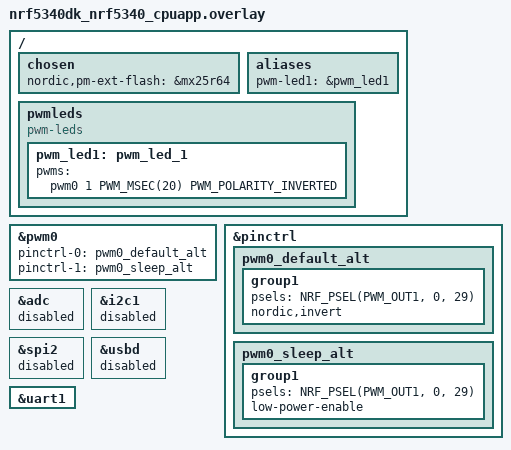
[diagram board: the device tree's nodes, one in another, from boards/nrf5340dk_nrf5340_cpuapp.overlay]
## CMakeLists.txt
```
#
# Copyright (c) 2022 Nordic Semiconductor ASA
#
# SPDX-License-Identifier: LicenseRef-Nordic-5-Clause
#

cmake_minimum_required(VERSION 3.20.0)

get_filename_component(MATTER_MODULE_ROOT $ENV{ZEPHYR_BASE}/../modules/lib/matter REALPATH)

# Set Kconfig root files that will be processed as a first Kconfig for used child images.
set(mcuboot_KCONFIG_ROOT ${MATTER_MODULE_ROOT}/config/nrfconnect/chip-module/Kconfig.mcuboot.root)
set(multiprotocol_rpmsg_KCONFIG_ROOT ${MATTER_MODULE_ROOT}/config/nrfconnect/chip-module/Kconfig.multiprotocol_rpmsg.root)
set(hci_rpmsg_KCONFIG_ROOT ${MATTER_MODULE_ROOT}/config/nrfconnect/chip-module/Kconfig.hci_rpmsg.root)

# For prj.conf the CONF_FILE is empty. In other case extract the exact file name from the path string.
if(CONF_FILE)
    get_filename_component(CONFIG_FILE_NAME ${CONF_FILE} NAME)
endif()

if(NOT CONFIG_FILE_NAME STREQUAL "prj_no_dfu.conf")
    set(PM_STATIC_YML_FILE ${CMAKE_CURRENT_SOURCE_DIR}/configuration/${BOARD}/pm_static_dfu.yml)
endif()

find_package(Zephyr HINTS $ENV{ZEPHYR_BASE})

project(matter-bridge)

set(COMMON_ROOT ${ZEPHYR_NRF_MODULE_DIR}/samples/matter/common)
set(NLIO_ROOT ${MATTER_MODULE_ROOT}/third_party/nlio/repo)
include(${MATTER_MODULE_ROOT}/config/nrfconnect/app/enable-gnu-std.cmake)
include(${MATTER_MODULE_ROOT}/src/app/chip_data_model.cmake)

# NORDIC SDK APP START
target_include_directories(app PRIVATE
    src
    ${COMMON_ROOT}/src
    ${NLIO_ROOT}/include
    ${MATTER_MODULE_ROOT}/zzz_generated/app-common
)

target_sources(app PRIVATE
    src/app_task.cpp
    src/main.cpp
    src/zigbee_shell.cpp
    src/Device.cpp
    src/zap-generated/IMClusterCommandHandler.cpp
    src/zap-generated/callback-stub.cpp
    ${COMMON_ROOT}/src/led_widget.cpp
)

if(CONFIG_CHIP_OTA_REQUESTOR OR CONFIG_MCUMGR_TRANSPORT_BT)
    target_sources(app PRIVATE ${COMMON_ROOT}/src/ota_util.cpp)
endif()

if(CONFIG_MCUMGR_TRANSPORT_BT)
    target_sources(app PRIVATE ${COMMON_ROOT}/src/dfu_over_smp.cpp)
endif()

chip_configure_data_model(app
    INCLUDE_SERVER
    BYPASS_IDL
    GEN_DIR src/zap-generated
    ZAP_FILE ${CMAKE_CURRENT_SOURCE_DIR}/src/bridge.zap
)
# NORDIC SDK APP END
```

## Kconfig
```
#
# Copyright (c) 2022 Nordic Semiconductor
#
# SPDX-License-Identifier: LicenseRef-Nordic-5-Clause
#
mainmenu "Matter Bridge sample application"

# Sample configuration used for Thread networking
if NET_L2_OPENTHREAD

choice OPENTHREAD_NORDIC_LIBRARY_CONFIGURATION
	default OPENTHREAD_NORDIC_LIBRARY_FTD
endchoice

choice OPENTHREAD_DEVICE_TYPE
	default OPENTHREAD_FTD
endchoice

endif # NET_L2_OPENTHREAD

config ZIGBEE_SHELL_DEVICE_NAME
	string "UART device name for Zigbee shell"
	default "UART_1"

source "${ZEPHYR_BASE}/../modules/lib/matter/config/nrfconnect/chip-module/Kconfig.features"
source "${ZEPHYR_BASE}/../modules/lib/matter/config/nrfconnect/chip-module/Kconfig.defaults"
source "Kconfig.zephyr"
```

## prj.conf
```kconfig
#
# Copyright (c) 2022 Nordic Semiconductor ASA
#
# SPDX-License-Identifier: LicenseRef-Nordic-5-Clause
#

# This sample uses Kconfig.defaults to set options common for all
# samples. This file should contain only options specific for this sample
# or overrides of default values.

# Enable CHIP
CONFIG_CHIP=y
CONFIG_CHIP_PROJECT_CONFIG="src/chip_project_config.h"
# 32768 == 0x8000
CONFIG_CHIP_DEVICE_PRODUCT_ID=32768
CONFIG_STD_CPP14=y

# Enable CHIP pairing automatically on application start.
CONFIG_CHIP_ENABLE_PAIRING_AUTOSTART=y

# Add support for LEDs and buttons on Nordic development kits
CONFIG_DK_LIBRARY=y

# Bluetooth Low Energy configuration
CONFIG_BT_DEVICE_NAME="MatterBridge"

# Other settings
CONFIG_THREAD_NAME=y
CONFIG_MPU_STACK_GUARD=y
CONFIG_RESET_ON_FATAL_ERROR=n

CONFIG_UART_ASYNC_API=y
CONFIG_UART_1_ASYNC=y
CONFIG_UART_1_INTERRUPT_DRIVEN=n
CONFIG_UART_1_NRF_HW_ASYNC=y
CONFIG_UART_1_NRF_HW_ASYNC_TIMER=2
CONFIG_NRFX_TIMER2=y
```

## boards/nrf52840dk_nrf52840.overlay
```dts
/* Copyright (c) 2022 Nordic Semiconductor ASA
 *
 * SPDX-License-Identifier: LicenseRef-Nordic-5-Clause
 */

/ {
	chosen {
		nordic,pm-ext-flash = &mx25r64;
	};
};


/ {
	/*
	* In some default configurations within the nRF Connect SDK,
	* e.g. on nRF52840, the chosen zephyr,entropy node is &cryptocell.
	* This devicetree overlay ensures that default is overridden wherever it
	* is set, as this application uses the RNG node for entropy exclusively.
	*/
	chosen {
		zephyr,entropy = &rng;
	};
};
```

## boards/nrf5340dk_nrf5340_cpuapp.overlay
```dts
/* Copyright (c) 2022 Nordic Semiconductor ASA
 *
 * SPDX-License-Identifier: LicenseRef-Nordic-5-Clause
 */

/ {
	chosen {
		nordic,pm-ext-flash = &mx25r64;
	};

	/*
	* By default, PWM module is only configured for led0 (LED1 on the board).
	* The light bulb app, however, uses LED2 to show the state of the lighting,
	* including its brightness level.
	*/
	aliases {
		pwm-led1 = &pwm_led1;
	};

	pwmleds {
		compatible = "pwm-leds";
		pwm_led1: pwm_led_1 {
			pwms = < &pwm0 1 PWM_MSEC(20) PWM_POLARITY_INVERTED>;
		};
	};
};

&pwm0 {
	pinctrl-0 = <&pwm0_default_alt>;
	pinctrl-1 = <&pwm0_sleep_alt>;
	pinctrl-names = "default", "sleep";
};

&pinctrl {
	pwm0_default_alt: pwm0_default_alt {
		group1 {
			psels = <NRF_PSEL(PWM_OUT1, 0, 29)>;
			nordic,invert;
		};
	};

	pwm0_sleep_alt: pwm0_sleep_alt {
		group1 {
			psels = <NRF_PSEL(PWM_OUT1, 0, 29)>;
			low-power-enable;
		};
	};
};

/* Disable unused peripherals to reduce power consumption */
&adc {
	status = "disabled";
};
&i2c1 {
	status = "disabled";
};
&spi2 {
	status = "disabled";
};
&usbd {
	status = "disabled";
};

/* Used to talk to the Zigbee board */
&uart1 {
	status = "okay";
};
```

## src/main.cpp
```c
/*
 * Copyright (c) 2022 Nordic Semiconductor ASA
 *
 * SPDX-License-Identifier: LicenseRef-Nordic-5-Clause
 */

#include "app_task.h"

#include <zephyr/logging/log.h>

#include <lib/support/CHIPMem.h>
#include <platform/CHIPDeviceLayer.h>

LOG_MODULE_REGISTER(app);

using namespace ::chip::DeviceLayer;

int main()
{
	int ret = 0;
	CHIP_ERROR err = CHIP_NO_ERROR;

	err = chip::Platform::MemoryInit();
	if (err != CHIP_NO_ERROR) {
		LOG_ERR("Platform::MemoryInit() failed");
		goto exit;
	}

	LOG_INF("Init CHIP stack");
	err = PlatformMgr().InitChipStack();
	if (err != CHIP_NO_ERROR) {
		LOG_ERR("PlatformMgr().InitChipStack() failed");
		goto exit;
	}

	LOG_INF("Starting CHIP task");
	err = PlatformMgr().StartEventLoopTask();
	if (err != CHIP_NO_ERROR) {
		LOG_ERR("PlatformMgr().StartEventLoopTask() failed");
		goto exit;
	}

	LOG_INF("Init Thread stack");
	err = ThreadStackMgr().InitThreadStack();
	if (err != CHIP_NO_ERROR) {
		LOG_ERR("ThreadStackMgr().InitThreadStack() failed");
		goto exit;
	}

	err = ConnectivityMgr().SetThreadDeviceType(ConnectivityManager::kThreadDeviceType_MinimalEndDevice);
	if (err != CHIP_NO_ERROR) {
		LOG_ERR("ConnectivityMgr().SetThreadDeviceType() failed");
		goto exit;
	}

	ret = GetAppTask().StartApp();
	if (ret != 0) {
		err = chip::System::MapErrorZephyr(ret);
	}

exit:
	return err == CHIP_NO_ERROR ? EXIT_SUCCESS : EXIT_FAILURE;
}
```

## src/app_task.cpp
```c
/*
 * Copyright (c) 2022 Nordic Semiconductor ASA
 *
 * SPDX-License-Identifier: LicenseRef-Nordic-5-Clause
 */

#include "app_task.h"
#include "led_widget.h"
#include "zigbee_shell.h"
#include "Device.h"

#include <app-common/zap-generated/attributes/Accessors.h>
#include <app/CommandHandler.h>
#include <app/reporting/reporting.h>
#include <app/server/OnboardingCodesUtil.h>
#include <app/server/Server.h>
#include <app/util/attribute-storage.h>
#include <credentials/DeviceAttestationCredsProvider.h>
#include <credentials/examples/DeviceAttestationCredsExample.h>
#include <lib/support/ZclString.h>
#include <platform/CHIPDeviceLayer.h>

#include <vector>

#include <dk_buttons_and_leds.h>

#include <zephyr/logging/log.h>
#include <zephyr/kernel.h>

LOG_MODULE_DECLARE(app);

using namespace ::chip;
using namespace ::chip::app;
using namespace ::chip::Credentials;
using namespace ::chip::DeviceLayer;

namespace
{
static constexpr size_t kAppEventQueueSize = 10;
static constexpr uint32_t kFactoryResetTriggerTimeout = 6000;

K_MSGQ_DEFINE(sAppEventQueue, sizeof(AppEvent), kAppEventQueueSize, alignof(AppEvent));
LEDWidget sStatusLED;
LEDWidget sUnusedLED;
LEDWidget sUnusedLED_1;
LEDWidget sUnusedLED_2;

ZigbeeShell sZbShell;

#define ZB_HA_DIMMABLE_LIGHT_DEVICE_ID  0x0101
#define ZB_AF_HA_PROFILE_ID		0x0104

static const int kNodeLabelSize = 32;
// Current ZCL implementation of Struct uses a max-size array of 254 bytes
static const int kDescriptorAttributeArraySize = 254;
static const int kFixedLabelAttributeArraySize = 254;

static EndpointId gCurrentEndpointId;
static EndpointId gFirstDynamicEndpointId;
static Device * gDevices[CHIP_DEVICE_CONFIG_DYNAMIC_ENDPOINT_COUNT]; // number of dynamic endpoints count

// Bridged devices
//std::vector<Device> Lights(CHIP_DEVICE_CONFIG_DYNAMIC_ENDPOINT_COUNT, Device("Default", "None"));
std::vector<Device> Lights(CHIP_DEVICE_CONFIG_DYNAMIC_ENDPOINT_COUNT, Device());

// (taken from chip-devices.xml)
#define DEVICE_TYPE_BRIDGED_NODE 0x0013
// (taken from lo-devices.xml)
#define DEVICE_TYPE_LO_ON_OFF_LIGHT 0x0100

// (taken from chip-devices.xml)
#define DEVICE_TYPE_ROOT_NODE 0x0016
// (taken from chip-devices.xml)
#define DEVICE_TYPE_BRIDGE 0x000e

// Device Version for dynamic endpoints:
#define DEVICE_VERSION_DEFAULT 1

/* REVISION definitions:
 */

#define ZCL_DESCRIPTOR_CLUSTER_REVISION (1u)
#define ZCL_BRIDGED_DEVICE_BASIC_INFORMATION_CLUSTER_REVISION (1u)
#define ZCL_FIXED_LABEL_CLUSTER_REVISION (1u)
#define ZCL_ON_OFF_CLUSTER_REVISION (4u)
#define ZCL_TEMPERATURE_SENSOR_CLUSTER_REVISION (4u)
#define ZCL_BRIDGED_DEVICE_BASIC_INFORMATION_FEATURE_MAP (0u)
#define ZCL_TEMPERATURE_SENSOR_FEATURE_MAP (0u)

/* BRIDGED DEVICE ENDPOINT: contains the following clusters:
   - On/Off
   - Descriptor
   - Bridged Device Basic Information
*/

// Declare On/Off cluster attributes
DECLARE_DYNAMIC_ATTRIBUTE_LIST_BEGIN(onOffAttrs)
DECLARE_DYNAMIC_ATTRIBUTE(Clusters::OnOff::Attributes::OnOff::Id, BOOLEAN, 1, 0), /* on/off */
    DECLARE_DYNAMIC_ATTRIBUTE(Clusters::OnOff::Attributes::ClusterRevision::Id, INT16U, ZCL_ON_OFF_CLUSTER_REVISION, 0),
	DECLARE_DYNAMIC_ATTRIBUTE_LIST_END();

// Declare Descriptor cluster attributes
DECLARE_DYNAMIC_ATTRIBUTE_LIST_BEGIN(descriptorAttrs)
DECLARE_DYNAMIC_ATTRIBUTE(Clusters::Descriptor::Attributes::DeviceTypeList::Id, ARRAY, kDescriptorAttributeArraySize,
                          0), /* device list */
    DECLARE_DYNAMIC_ATTRIBUTE(Clusters::Descriptor::Attributes::ServerList::Id, ARRAY, kDescriptorAttributeArraySize,
                              0), /* server list */
    DECLARE_DYNAMIC_ATTRIBUTE(Clusters::Descriptor::Attributes::ClientList::Id, ARRAY, kDescriptorAttributeArraySize,
                              0), /* client list */
    DECLARE_DYNAMIC_ATTRIBUTE(Clusters::Descriptor::Attributes::PartsList::Id, ARRAY, kDescriptorAttributeArraySize,
                              0), /* parts list */
    DECLARE_DYNAMIC_ATTRIBUTE(Clusters::Descriptor::Attributes::ClusterRevision::Id, INT16U, ZCL_DESCRIPTOR_CLUSTER_REVISION,
                              0), /* cluster revision */
	DECLARE_DYNAMIC_ATTRIBUTE_LIST_END();

// Declare Bridged Device Basic Information cluster attributes
DECLARE_DYNAMIC_ATTRIBUTE_LIST_BEGIN(bridgedDeviceBasicAttrs)
DECLARE_DYNAMIC_ATTRIBUTE(chip::app::Clusters::BridgedDeviceBasicInformation::Attributes::NodeLabel::Id, CHAR_STRING,
                          kNodeLabelSize, 0), /* NodeLabel */
    DECLARE_DYNAMIC_ATTRIBUTE(chip::app::Clusters::BridgedDeviceBasicInformation::Attributes::Reachable::Id, BOOLEAN, 1,
                              0), /* Reachable */
    DECLARE_DYNAMIC_ATTRIBUTE(chip::app::Clusters::BridgedDeviceBasicInformation::Attributes::ClusterRevision::Id, INT16U,
                              ZCL_BRIDGED_DEVICE_BASIC_INFORMATION_CLUSTER_REVISION, 0), /* cluster revision */
	DECLARE_DYNAMIC_ATTRIBUTE_LIST_END();

// Declare Cluster List for Bridged Light endpoint
// TODO: It's not clear whether it would be better to get the command lists from
// the ZAP config on our last fixed endpoint instead.
constexpr CommandId onOffIncomingCommands[] = {
    app::Clusters::OnOff::Commands::Off::Id,
    app::Clusters::OnOff::Commands::On::Id,
    app::Clusters::OnOff::Commands::Toggle::Id,
    app::Clusters::OnOff::Commands::OffWithEffect::Id,
    app::Clusters::OnOff::Commands::OnWithRecallGlobalScene::Id,
    app::Clusters::OnOff::Commands::OnWithTimedOff::Id,
    kInvalidCommandId,
};

DECLARE_DYNAMIC_CLUSTER_LIST_BEGIN(bridgedLightClusters)
DECLARE_DYNAMIC_CLUSTER(Clusters::OnOff::Id, onOffAttrs, onOffIncomingCommands, nullptr),
    DECLARE_DYNAMIC_CLUSTER(Clusters::Descriptor::Id, descriptorAttrs, nullptr, nullptr),
    DECLARE_DYNAMIC_CLUSTER(chip::app::Clusters::BridgedDeviceBasicInformation::Id, bridgedDeviceBasicAttrs, nullptr,
                            nullptr) DECLARE_DYNAMIC_CLUSTER_LIST_END;

// Declare Bridged Light endpoint
DECLARE_DYNAMIC_ENDPOINT(bridgedLightEndpoint, bridgedLightClusters);

bool sIsThreadProvisioned;
bool sIsThreadEnabled;
bool sHaveBLEConnections;

k_timer sFunctionTimer;
} /* namespace */

AppTask AppTask::sAppTask;

DataVersion gLightDataVersions[ArraySize(bridgedLightClusters)];

const EmberAfDeviceType gRootDeviceTypes[]          = { { DEVICE_TYPE_ROOT_NODE, DEVICE_VERSION_DEFAULT } };
const EmberAfDeviceType gAggregateNodeDeviceTypes[] = { { DEVICE_TYPE_BRIDGE, DEVICE_VERSION_DEFAULT } };

const EmberAfDeviceType gBridgedOnOffDeviceTypes[] = { { DEVICE_TYPE_LO_ON_OFF_LIGHT, DEVICE_VERSION_DEFAULT },
                                                       { DEVICE_TYPE_BRIDGED_NODE, DEVICE_VERSION_DEFAULT } };


int AddDeviceEndpoint(Device * dev, EmberAfEndpointType * ep, const Span<const EmberAfDeviceType> & deviceTypeList,
                      const Span<DataVersion> & dataVersionStorage, chip::EndpointId parentEndpointId)
{
    uint8_t index = 0;
    while (index < CHIP_DEVICE_CONFIG_DYNAMIC_ENDPOINT_COUNT)
    {
        if (NULL == gDevices[index])
        {
            gDevices[index] = dev;
            EmberAfStatus ret;
            while (true)
            {
                dev->SetEndpointId(gCurrentEndpointId);
                ret =
                    emberAfSetDynamicEndpoint(index, gCurrentEndpointId, ep, dataVersionStorage, deviceTypeList, parentEndpointId);
                if (ret == EMBER_ZCL_STATUS_SUCCESS)
                {
                    ChipLogProgress(DeviceLayer, "Added device %s to dynamic endpoint %d (index=%d)", dev->GetName(),
                                    gCurrentEndpointId, index);
                    return index;
                }
                else if (ret != EMBER_ZCL_STATUS_DUPLICATE_EXISTS)
                {
                    return -1;
                }
                // Handle wrap condition
                if (++gCurrentEndpointId < gFirstDynamicEndpointId)
                {
                    gCurrentEndpointId = gFirstDynamicEndpointId;
                }
            }
        }
        index++;
    }
    ChipLogError(DeviceLayer, "Failed to add dynamic endpoint: No endpoints available!");
	return -1;
}

CHIP_ERROR RemoveDeviceEndpoint(Device * dev)
{
	for (uint8_t index = 0; index < CHIP_DEVICE_CONFIG_DYNAMIC_ENDPOINT_COUNT; index++)
	{
		if (gDevices[index] == dev)
		{
			EndpointId ep   = emberAfClearDynamicEndpoint(index);
			gDevices[index] = NULL;
			ChipLogProgress(DeviceLayer, "Removed device %s from dynamic endpoint %d (index=%d)", dev->GetName(), ep, index);
			// Silence complaints about unused ep when progress logging
			// disabled.
			UNUSED_VAR(ep);
			return CHIP_NO_ERROR;
		}
	}
	return CHIP_ERROR_INTERNAL;
}

EmberAfStatus HandleReadBridgedDeviceBasicAttribute(Device * dev, chip::AttributeId attributeId, uint8_t * buffer,
						    uint16_t maxReadLength)
{
	using namespace chip::app::Clusters::BridgedDeviceBasicInformation::Attributes;
	ChipLogProgress(DeviceLayer, "HandleReadBridgedDeviceBasicAttribute: attrId=%" PRIu32 ", maxReadLength=%u", attributeId,
                    maxReadLength);

	if ((attributeId == Reachable::Id) && (maxReadLength == 1))
	{
		*buffer = dev->IsReachable() ? 1 : 0;
	}
	else if ((attributeId == NodeLabel::Id) && (maxReadLength == 32))
	{
		MutableByteSpan zclNameSpan(buffer, maxReadLength);
		MakeZclCharString(zclNameSpan, dev->GetName());
	}
	else if ((attributeId == FeatureMap::Id) && (maxReadLength == 4))
	{
		uint32_t featureMap = ZCL_BRIDGED_DEVICE_BASIC_INFORMATION_FEATURE_MAP;
		memcpy(buffer, &featureMap, sizeof(featureMap));
	}
	else if ((attributeId == ClusterRevision::Id) && (maxReadLength == 4))
	{
		uint16_t clusterRevision = ZCL_BRIDGED_DEVICE_BASIC_INFORMATION_CLUSTER_REVISION;
		memcpy(buffer, &clusterRevision, sizeof(clusterRevision));
	}
	else
	{
		return EMBER_ZCL_STATUS_FAILURE;
	}

	return EMBER_ZCL_STATUS_SUCCESS;
}

EmberAfStatus HandleReadOnOffAttribute(Device * dev, chip::AttributeId attributeId, uint8_t * buffer, uint16_t maxReadLength)
{
	ChipLogProgress(DeviceLayer, "HandleReadOnOffAttribute: attrId=%" PRIu32 ", maxReadLength=%u", attributeId, maxReadLength);

	if ((attributeId == Clusters::OnOff::Attributes::OnOff::Id) && (maxReadLength == 1))
	{
		*buffer = dev->IsOn() ? 1 : 0;
	}
	else if ((attributeId == Clusters::OnOff::Attributes::ClusterRevision::Id) && (maxReadLength == 4))
	{
		uint16_t clusterRevision = ZCL_ON_OFF_CLUSTER_REVISION;
		memcpy(buffer, &clusterRevision, sizeof(clusterRevision));
	}
	else
	{
		return EMBER_ZCL_STATUS_FAILURE;
	}

	return EMBER_ZCL_STATUS_SUCCESS;
}

EmberAfStatus HandleWriteOnOffAttribute(Device * dev, chip::AttributeId attributeId, uint8_t * buffer)
{
	ChipLogProgress(DeviceLayer, "HandleWriteOnOffAttribute: attrId=%" PRIu32, attributeId);

	ReturnErrorCodeIf((attributeId != Clusters::OnOff::Attributes::OnOff::Id) || (!dev->IsReachable()), EMBER_ZCL_STATUS_FAILURE);
	dev->SetOnOff(*buffer == 1);
	sZbShell.ZclCmd(dev->GetZbAddr(), dev->GetZbEp(), ZigbeeShell::kCluster_OnOff, (*buffer == 1)?(true):(false));
	return EMBER_ZCL_STATUS_SUCCESS;
}

EmberAfStatus emberAfExternalAttributeReadCallback(EndpointId endpoint, ClusterId clusterId,
						   const EmberAfAttributeMetadata * attributeMetadata, uint8_t * buffer,
						   uint16_t maxReadLength)
{
    using namespace Clusters;

	uint16_t endpointIndex = emberAfGetDynamicIndexFromEndpoint(endpoint);

	if ((endpointIndex < CHIP_DEVICE_CONFIG_DYNAMIC_ENDPOINT_COUNT) && (gDevices[endpointIndex] != NULL))
	{
		Device * dev = gDevices[endpointIndex];

		if (clusterId == BridgedDeviceBasicInformation::Id)
		{
			return HandleReadBridgedDeviceBasicAttribute(dev, attributeMetadata->attributeId, buffer, maxReadLength);
		}
		else if (clusterId == OnOff::Id)
		{
			return HandleReadOnOffAttribute(dev, attributeMetadata->attributeId, buffer, maxReadLength);
		}
	}

	return EMBER_ZCL_STATUS_FAILURE;
}

EmberAfStatus emberAfExternalAttributeWriteCallback(EndpointId endpoint, ClusterId clusterId,
						    const EmberAfAttributeMetadata * attributeMetadata, uint8_t * buffer)
{
	uint16_t endpointIndex = emberAfGetDynamicIndexFromEndpoint(endpoint);

	if (endpointIndex < CHIP_DEVICE_CONFIG_DYNAMIC_ENDPOINT_COUNT)
	{
		Device * dev = gDevices[endpointIndex];

		if ((dev->IsReachable()) && (clusterId == Clusters::OnOff::Id))
		{
			return HandleWriteOnOffAttribute(dev, attributeMetadata->attributeId, buffer);
		}
	}

	return EMBER_ZCL_STATUS_FAILURE;
}

namespace {
void CallReportingCallback(intptr_t closure)
{
    auto path = reinterpret_cast<app::ConcreteAttributePath *>(closure);
    MatterReportingAttributeChangeCallback(*path);
    Platform::Delete(path);
}

void ScheduleReportingCallback(Device * dev, ClusterId cluster, AttributeId attribute)
{
    auto * path = Platform::New<app::ConcreteAttributePath>(dev->GetEndpointId(), cluster, attribute);
    DeviceLayer::PlatformMgr().ScheduleWork(CallReportingCallback, reinterpret_cast<intptr_t>(path));
}
} // anonymous namespace

void HandleDeviceStatusChanged(Device * dev, Device::Changed_t itemChangedMask)
{
    using namespace chip::app::Clusters;
	if (itemChangedMask & Device::kChanged_Reachable)
	{
		ScheduleReportingCallback(dev, BridgedDeviceBasicInformation::Id, BridgedDeviceBasicInformation::Attributes::Reachable::Id);
	}

	if (itemChangedMask & Device::kChanged_State)
	{
		ScheduleReportingCallback(dev, OnOff::Id, OnOff::Attributes::OnOff::Id);
	}

	if (itemChangedMask & Device::kChanged_Name)
	{
		ScheduleReportingCallback(dev, BridgedDeviceBasicInformation::Id, BridgedDeviceBasicInformation::Attributes::NodeLabel::Id);
	}
}

bool emberAfActionsClusterInstantActionCallback(app::CommandHandler * commandObj, const app::ConcreteCommandPath & commandPath,
                                                const Clusters::Actions::Commands::InstantAction::DecodableType & commandData)
{
    // No actions are implemented, just return status NotFound.
    commandObj->AddStatus(commandPath, Protocols::InteractionModel::Status::NotFound);
    return true;
}


int AppTask::Init()
{
	int ret;

	/* Initialize LEDs */
	LEDWidget::InitGpio();
	LEDWidget::SetStateUpdateCallback(LEDStateUpdateHandler);

	sStatusLED.Init(DK_LED1);
	sUnusedLED.Init(DK_LED2);
	sUnusedLED_1.Init(DK_LED3);
	sUnusedLED_2.Init(DK_LED4);

	UpdateStatusLED();

	memset(gDevices, 0, sizeof(gDevices));

	// Whenever bridged device changes its state
	for (size_t i = 0; i < Lights.size(); ++i)
	{
		Lights[i].SetChangeCallback(&HandleDeviceStatusChanged);
	}

	/* Init Zigbee stack */
	sZbShell.SetEventCallback(ZigbeeEventHandler);
	ret = sZbShell.BdbStart();
	if (ret) {
		LOG_ERR("BdbStart() failed");
		return ret;
	}

	/* Initialize buttons */
	ret = dk_buttons_init(ButtonEventHandler);
	if (ret) {
		LOG_ERR("dk_buttons_init() failed");
		return ret;
	}

	/* Initialize function timer */
	k_timer_init(&sFunctionTimer, &AppTask::TimerEventHandler, nullptr);
	k_timer_user_data_set(&sFunctionTimer, this);

	/* Init ZCL Data Model and start server */
	static chip::CommonCaseDeviceServerInitParams initParams;
	(void) initParams.InitializeStaticResourcesBeforeServerInit();
	chip::Server::GetInstance().Init(initParams);

	/* Initialize device attestation config */
	SetDeviceAttestationCredentialsProvider(Examples::GetExampleDACProvider());
	ConfigurationMgr().LogDeviceConfig();
	PrintOnboardingCodes(chip::RendezvousInformationFlags(chip::RendezvousInformationFlag::kBLE));

	// Set starting endpoint id where dynamic endpoints will be assigned, which
	// will be the next consecutive endpoint id after the last fixed endpoint.
	gFirstDynamicEndpointId = static_cast<chip::EndpointId>(
		static_cast<int>(emberAfEndpointFromIndex(static_cast<uint16_t>(emberAfFixedEndpointCount() - 1))) + 1);
	gCurrentEndpointId = gFirstDynamicEndpointId;

	// Disable last fixed endpoint, which is used as a placeholder for all of the
	// supported clusters so that ZAP will generate the requisite code.
	emberAfEndpointEnableDisable(emberAfEndpointFromIndex(static_cast<uint16_t>(emberAfFixedEndpointCount() - 1)), false);

	// A bridge has root node device type on EP0 and aggregate node device type (bridge) at EP1
	emberAfSetDeviceTypeList(0, Span<const EmberAfDeviceType>(gRootDeviceTypes));
	emberAfSetDeviceTypeList(1, Span<const EmberAfDeviceType>(gAggregateNodeDeviceTypes));

	return 0;
}

int AppTask::StartApp()
{
	int ret = Init();

	if (ret) {
		LOG_ERR("AppTask.Init() failed");
		return ret;
	}

	AppEvent event = {};

	while (true) {
		k_msgq_get(&sAppEventQueue, &event, K_FOREVER);
		DispatchEvent(event);
	}
}

void AppTask::PostEvent(const AppEvent &event)
{
	if (k_msgq_put(&sAppEventQueue, &event, K_NO_WAIT)) {
		LOG_INF("Failed to post event to app task event queue");
	}
}

void AppTask::DispatchEvent(const AppEvent &event)
{
	int err;
	uint16_t InputCluster[] = {ZigbeeShell::Cluster_t::kCluster_OnOff};
	uint16_t OutputCluster[] = {};

	switch (event.Type) {
	case AppEvent::FunctionPress:
		FunctionPressHandler();
		break;
	case AppEvent::FunctionRelease:
		FunctionReleaseHandler();
		break;
	case AppEvent::FunctionTimer:
		FunctionTimerEventHandler();
		break;
	case AppEvent::UpdateLedState:
		event.UpdateLedStateEvent.LedWidget->UpdateState();
		break;
	case AppEvent::NetworkRejoin:
		err = sZbShell.ZdoMatchDesc(0xfffd, 0xfffd, ZB_AF_HA_PROFILE_ID, 1, InputCluster, 0, OutputCluster);
		if (err) {
			LOG_ERR("Fail to broadcast MatchDesc");
		}
		break;
	case AppEvent::DeviceAnnounceRsp:
		err = sZbShell.ZdoActiveEpReq(event.zdo.addr);
		if (err) {
			LOG_ERR("Fail to request active ep");
		}
		break;
	case AppEvent::ActiveEpRsp:
		err = sZbShell.ZdoSimpleDescReq(event.zdo.addr, event.zdo.ep);
		if (err) {
			LOG_ERR("Fail to request simple descriptor");
		}
		break;
	case AppEvent::SimpleDescRsp:
		err = sZbShell.ZclAttrRead(event.zdo.addr,
					   event.zdo.ep,
					   ZB_AF_HA_PROFILE_ID,
					   ZigbeeShell::kCluster_OnOff,
					   ZigbeeShell::kOnOffAttr_OnOff);
		if (err) {
			LOG_ERR("Fail to request simple descriptor");
		}
		break;
	case AppEvent::StartNetworkSteering:
		err = sZbShell.NetworkSteering();
		if (err) {
			LOG_ERR("Fail to start network steering");
		}
		break;
	default:
		LOG_INF("Unknown event received");
		break;
	}
}

void AppTask::FunctionPressHandler()
{
	sAppTask.StartFunctionTimer(kFactoryResetTriggerTimeout);
	sAppTask.mFunction = TimerFunction::FactoryReset;
}

void AppTask::FunctionReleaseHandler()
{
	if (sAppTask.mFunction == TimerFunction::FactoryReset) {
		sUnusedLED_2.Set(false);
		sUnusedLED_1.Set(false);
		sUnusedLED.Set(false);

		UpdateStatusLED();

		sAppTask.CancelFunctionTimer();
		sAppTask.mFunction = TimerFunction::NoneSelected;
		LOG_INF("Factory Reset has been Canceled");
	}
}

void AppTask::FunctionTimerEventHandler()
{
	if (sAppTask.mFunction == TimerFunction::FactoryReset) {
		sAppTask.mFunction = TimerFunction::NoneSelected;
		LOG_INF("Factory Reset triggered");

		sStatusLED.Set(true);
		sUnusedLED.Set(true);
		sUnusedLED_1.Set(true);
		sUnusedLED_2.Set(true);

		ConfigurationMgr().InitiateFactoryReset();
	}
}

void AppTask::LEDStateUpdateHandler(LEDWidget &ledWidget)
{
	sAppTask.PostEvent(AppEvent{ AppEvent::UpdateLedState, &ledWidget });
}

void AppTask::UpdateStatusLED()
{
	/* Update the status LED.
	 *
	 * If thread and service provisioned, keep the LED On constantly.
	 *
	 * If the system has ble connection(s) uptill the stage above, THEN blink the LED at an even
	 * rate of 100ms.
	 *
	 * Otherwise, blink the LED On for a very short time. */
	if (sIsThreadProvisioned && sIsThreadEnabled) {
		sStatusLED.Set(true);
	} else if (sHaveBLEConnections) {
		sStatusLED.Blink(100, 100);
	} else {
		sStatusLED.Blink(50, 950);
	}
}

void AppTask::ChipEventHandler(const ChipDeviceEvent *event, intptr_t /* arg */)
{
	switch (event->Type) {
	case DeviceEventType::kCHIPoBLEAdvertisingChange:
		sHaveBLEConnections = ConnectivityMgr().NumBLEConnections() != 0;
		UpdateStatusLED();
		break;
	case DeviceEventType::kThreadStateChange:
		sIsThreadProvisioned = ConnectivityMgr().IsThreadProvisioned();
		sIsThreadEnabled = ConnectivityMgr().IsThreadEnabled();
		UpdateStatusLED();
		break;
	default:
		break;
	}
}

void AppTask::ButtonEventHandler(uint32_t buttonState, uint32_t hasChanged)
{
	if (DK_BTN1_MSK & buttonState & hasChanged) {
		GetAppTask().PostEvent(AppEvent{ AppEvent::FunctionPress });
	} else if (DK_BTN1_MSK & hasChanged) {
		GetAppTask().PostEvent(AppEvent{ AppEvent::FunctionRelease });
	}

	if (DK_BTN2_MSK & buttonState & hasChanged) {
		GetAppTask().PostEvent(AppEvent{ AppEvent::StartNetworkSteering });
	}
}

void AppTask::ZigbeeEventHandler(ZigbeeShell * shell, ZigbeeShell::Event_t event)
{
	LOG_INF("Zigbee event: %d", event);
	switch (event) {
	case ZigbeeShell::kEvent_NetworkRejoin:
		GetAppTask().PostEvent(AppEvent{ AppEvent::NetworkRejoin, shell->mEvent.Bdb});
		break;
	case ZigbeeShell::kEvent_DeviceAnnounceRsp:
		GetAppTask().PostEvent(AppEvent{ AppEvent::DeviceAnnounceRsp, shell->mEvent.Zdo});
		break;
	case ZigbeeShell::kEvent_ActiveEpRsp:
		GetAppTask().PostEvent(AppEvent{ AppEvent::ActiveEpRsp, shell->mEvent.Zdo});
		break;
	case ZigbeeShell::kEvent_SimpleDescRsp:
		LOG_INF("addr:0x%04hx ep:%d dev_id:0x%04hx",
			shell->mEvent.Zdo.addr,
			shell->mEvent.Zdo.ep,
			shell->mEvent.Zdo.dev_id);
		if (shell->mEvent.Zdo.dev_id != ZB_HA_DIMMABLE_LIGHT_DEVICE_ID) {
			return;
		}
		for (auto &light : Lights)
		{
			if ((light.GetZbAddr() == shell->mEvent.Zcl.addr) &&
				(light.GetZbEp() == shell->mEvent.Zcl.ep)) {
				LOG_INF("Device existed");
				return;
			}
		}
		for (auto &light : Lights)
		{
			if (!strcmp(light.GetName(), "none")) {
				if (AddDeviceEndpoint(&light, &bridgedLightEndpoint,
					Span<const EmberAfDeviceType>(gBridgedOnOffDeviceTypes),
								      Span<DataVersion>(gLightDataVersions), 1) == 0) {
					light.SetName("Light");
					light.SetZbAddr(shell->mEvent.Zdo.addr);
					light.SetZbEp(shell->mEvent.Zdo.ep);
					light.SetReachable(true);
					GetAppTask().PostEvent(AppEvent{ AppEvent::SimpleDescRsp, shell->mEvent.Zdo});
				} else {
					LOG_ERR("Zigbee event: %d", event);
				}
				break;
			}
		}
		break;
	case ZigbeeShell::kEvent_ZclAttrRead:
		for (auto &light : Lights)
		{
			if ((light.GetZbAddr() != shell->mEvent.Zcl.addr) ||
				(light.GetZbEp() != shell->mEvent.Zcl.ep)) {
				continue;
			}
			if (shell->mEvent.Zcl.cluster_id == ZigbeeShell::kCluster_OnOff &&
				shell->mEvent.Zcl.attr_id == ZigbeeShell::kOnOffAttr_OnOff &&
				shell->mEvent.Zcl.type == ZigbeeShell::kZclAttrType_BOOL) {
				if (!strncmp(shell->mEvent.Zcl.value, "True", shell->mEvent.Zcl.len)) {
					light.SetOnOff(true);
				} else if (!strncmp(shell->mEvent.Zcl.value, "False", shell->mEvent.Zcl.len)) {
					light.SetOnOff(false);
				} else {
					LOG_ERR("Wrong attr value");
				}
				break;
			}
		}
		break;
	default:
		LOG_WRN("Unknown event received");
		break;
	}

}

void AppTask::CancelFunctionTimer()
{
	k_timer_stop(&sFunctionTimer);
}

void AppTask::StartFunctionTimer(uint32_t timeoutInMs)
{
	k_timer_start(&sFunctionTimer, K_MSEC(timeoutInMs), K_NO_WAIT);
}

void AppTask::TimerEventHandler(k_timer *timer)
{
	GetAppTask().PostEvent(AppEvent{ AppEvent::FunctionTimer });
}
```

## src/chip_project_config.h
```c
/*
 * Copyright (c) 2022 Nordic Semiconductor ASA
 *
 * SPDX-License-Identifier: LicenseRef-Nordic-5-Clause
 */

/**
 *    @file
 *          Example project configuration file for CHIP.
 *
 *          This is a place to put application or project-specific overrides
 *          to the default configuration values for general CHIP features.
 *
 */

#pragma once

/* Use a default pairing code if one hasn't been provisioned in flash. */
#define CHIP_DEVICE_CONFIG_USE_TEST_SETUP_PIN_CODE 20202021
#define CHIP_DEVICE_CONFIG_USE_TEST_SETUP_DISCRIMINATOR 0xF00

// overrides CHIP_DEVICE_CONFIG_DYNAMIC_ENDPOINT_COUNT in CHIPProjectConfig
#define CHIP_DEVICE_CONFIG_DYNAMIC_ENDPOINT_COUNT 16
```

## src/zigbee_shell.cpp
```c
/*
 * Copyright (c) 2022 Nordic Semiconductor ASA
 *
 * SPDX-License-Identifier: LicenseRef-Nordic-5-Clause
 */

#include "zigbee_shell.h"
#include <zephyr/logging/log.h>
#include <zephyr/drivers/uart.h>

LOG_MODULE_DECLARE(zigbee_shell);

size_t ZigbeeShell::ShellRspHandler(ZigbeeShell *shell, const char *data, size_t len)
{
	char *p;

	p = strstr(data, ZB_SHELL_MSG_PROMPT);
	if (p != NULL) {
		LOG_DBG("Shell command finished");
		return p - data + strlen(ZB_SHELL_MSG_PROMPT);
	}

	return 0;
}

size_t ZigbeeShell::GeneralRspHandler(ZigbeeShell *shell, const char *data, size_t len)
{
	char *p;

	p = strstr((char *)data, ZB_SHELL_MSG_CMD_DONE);
	if (p != NULL) {
		LOG_DBG("General command finished - Done");
		shell->mZigbeeCmd.result = 0;
		return p - data + strlen(ZB_SHELL_MSG_CMD_DONE);
	}
	p = strstr((char *)data, ZB_SHELL_MSG_CMD_ERROR);
	if (p != NULL) {
		LOG_ERR("General command finished - Error");
		shell->mZigbeeCmd.result = -EINVAL;
		return p - data + strlen(ZB_SHELL_MSG_CMD_ERROR);
	}

	return 0;
}

size_t ZigbeeShell::ZclAttrReadRspHandler(ZigbeeShell *shell,const char *data, size_t len)
{
	char *p, *end;
	int attr_id;
	uint8_t type;
	size_t ret;

	p = strstr((char *)data, ZB_SHELL_MSG_CMD_ERROR);
	if (p != NULL) {
		LOG_ERR("Zcl attr read finished - Error");
		return p - data + strlen(ZB_SHELL_MSG_CMD_ERROR);
	}
	p = strstr((char *)data, ZB_SHELL_MSG_CMD_DONE);
	if (p == NULL) {
		LOG_DBG("Wait for more response");
		return 0;
	}
	ret = p - data + strlen(ZB_SHELL_MSG_CMD_DONE);
	p = strstr(data, "ID: ");
	if (p == NULL) {
		LOG_WRN("attr id missed");
		return ret;
	} else {
		p = p + strlen("ID: ");
		attr_id = strtol(p, &end, 10);
		if (p == end) {
			LOG_WRN("Can't get attr id");
			return ret;
		}
	}
	p = strstr(data, "Type: ");
	if (p == NULL) {
		LOG_WRN("attr type missed");
		return ret;
	} else {
		p = p + strlen("Type: ");
		type = strtol(p, &end, 16);
		if (p == end) {
			LOG_WRN("Can't get attr type");
			return ret;
		}
	}
	p = strstr(data, "Value: ");
	if (p == NULL) {
		LOG_WRN("Attr Value missed");
		return ret;
	}

	char *value_end = nullptr;

	p = p + strlen("Value: ");
	value_end = strstr(p, "\r\n");
	if (value_end == NULL) {
		LOG_WRN("Can't get attr value");
		return ret;
	}
	if ((value_end - p) > ZB_ZCL_MAX_ATTR_SIZE) {
		LOG_ERR("Fail to parse attr value");
		return 0;
	}
	memset(shell->mEvent.Zcl.value, 0, sizeof(shell->mEvent.Zcl.value));
	shell->mEvent.Zcl.len = value_end - p;
	shell->mEvent.Zcl.type = type;
	strncpy(shell->mEvent.Zcl.value, p, shell->mEvent.Zcl.len);
	LOG_INF("ID: %d Type: %x Value: %s", attr_id, type, shell->mEvent.Zcl.value);
	shell->mEvent_CB(shell, kEvent_ZclAttrRead);

	return ret;
}

size_t ZigbeeShell::ZdoActiveEpRspHandler(ZigbeeShell *shell, const char *data, size_t len)
{
	const char *p;
	uint16_t dev_addr;
	size_t ret;

	p = strstr((char *)data, ZB_SHELL_MSG_CMD_ERROR);
	if (p != NULL) {
		LOG_ERR("Zdo active endpoint request finished - Error");
		return p - data + strlen(ZB_SHELL_MSG_CMD_ERROR);
	}
	p = strstr((char *)data, ZB_SHELL_MSG_CMD_DONE);
	if (p == NULL) {
		LOG_DBG("Wait for more response");
		return 0;
	}
	ret = p - data + strlen(ZB_SHELL_MSG_CMD_DONE);
	p = data;
	for (;;) {
		p = strstr(p, "src_addr=");
		if (p == NULL) {
			break;
		} else {
			p = p + strlen("src_addr=");
			dev_addr = strtol(p, NULL, 16);
			p = strstr(p, "ep=");
			if (p == NULL) {
				break;
			} else {
				p = p + strlen("ep=");
				for (;;) {
					char *end;
					int ep;

					ep = strtol(p, &end, 10);
					if (p == end) {
						break;
					}
					shell->mEvent.Zdo.addr = dev_addr;
					shell->mEvent.Zdo.ep = ep;
					shell->mEvent_CB(shell, kEvent_ActiveEpRsp);
					if (*end == ',') {
						p = end + 1;
					} else {
						break;
					}
				}
			}
		}
	}
	return ret;
}

size_t ZigbeeShell::ZdoSimpleDescRspHandler(ZigbeeShell *shell, const char *data, size_t len)
{
	char *p;
	uint16_t dev_addr;
	size_t ret;

	p = strstr((char *)data, ZB_SHELL_MSG_CMD_ERROR);
	if (p != NULL) {
		LOG_ERR("Zdo simple descriptor request finished - Error");
		return p - data + strlen(ZB_SHELL_MSG_CMD_ERROR);
	}
	p = strstr((char *)data, ZB_SHELL_MSG_CMD_DONE);
	if (p == NULL) {
		LOG_DBG("Wait for more response");
		return 0;
	}
	ret = p - data + strlen(ZB_SHELL_MSG_CMD_DONE);
	p = strstr(data, "src_addr=");
	if (p == NULL) {
		return ret;
	} else {
		dev_addr = strtol(p + strlen("src_addr="), NULL, 16);
	}
	p = strstr(data, "ep=");
	if (p == NULL) {
		return ret;
	} else {
		char *end;
		int ep;
		int dev_id;

		p = p + strlen("ep=");
		ep = strtol(p, &end, 10);
		if (p != end) {
			p = strstr(data, "app_dev_id=");
			p = p + strlen("app_dev_id=");
			dev_id = strtol(p, &end, 16);
			if (p != end) {
				LOG_INF("addr: 0x%4hx, active ep: %d device id: %04hx",
					dev_addr, ep, dev_id);
				shell->mEvent.Zdo.addr = dev_addr;
				shell->mEvent.Zdo.ep = ep;
				shell->mEvent.Zdo.dev_id = dev_id;
				shell->mEvent_CB(shell, kEvent_SimpleDescRsp);
			}
		}
	}
	return ret;
}

void ZigbeeShell::UartWorkHandler(struct k_work *work)
{
	size_t ret = 0, parsed = 0, total_parsed = 0;

	ZigbeeShell *c = reinterpret_cast<ZigbeeShell*>((reinterpret_cast<char*>(work) - reinterpret_cast<int>((&(static_cast<ZigbeeShell*>(0)->mUartWork)))));
	if (c->mZigbeeCmd.handler == nullptr) {
		k_sem_give(&c->mCmdSem);
		return;
	}
	memset(c->mParserBuffer, 0, sizeof(c->mParserBuffer));
	ret = ring_buf_peek(&c->mShellRspRb, (uint8_t *)c->mParserBuffer, UNPARSED_BUF_LEN);
	if (ret == 0 || ret > UNPARSED_BUF_LEN) {
		LOG_ERR("Fail to peek ring buffer");
	}
	LOG_HEXDUMP_DBG(c->mParserBuffer, ret, "data to parse");
	parsed = c->mZigbeeCmd.handler(c, c->mParserBuffer, ret);
	if (parsed > 0) {
		k_sem_give(&c->mCmdSem);
	}
	total_parsed = (parsed > total_parsed) ? parsed : total_parsed;

	parsed = c->ParseShellMessage(c->mParserBuffer);
	total_parsed = (parsed > total_parsed) ? parsed : total_parsed;
	if (total_parsed > 0) {
		/* Remove parsed data from ring buffer */
		ret = ring_buf_get(&c->mShellRspRb, NULL, total_parsed);
		if(ret != total_parsed) {
			LOG_ERR("Fail to release from ring buffer");
		} else {
			LOG_INF("Release %d from buffer", ret);
		}
	}
}

int ZigbeeShell::WriteCmd(const char *cmd, ZigbeeResponseHandler rspHandler)
{
	int err = 0;
	size_t len;

	len = strlen(cmd);
	if (len + 2 > MAX_ZIGBEE_CMD_LEN) {
		LOG_INF("Not enough buffer to put Zigbee shell command");
		return -ENOMEM;
	}
	memset(mZigbeeCmd.command, 0, sizeof(mZigbeeCmd.command));
	memcpy(mZigbeeCmd.command, cmd, len);
	mZigbeeCmd.command[len] = '\r';
	mZigbeeCmd.command[len + 1] = '\n';
	mZigbeeCmd.handler = rspHandler;
	err = uart_tx(mUartDev, (const uint8_t *)mZigbeeCmd.command, strlen(mZigbeeCmd.command), 10);
	if (err) {
		LOG_ERR("uart_tx fail: %d", err);
	}
	k_sem_take(&mCmdSem, K_FOREVER);

	return mZigbeeCmd.result;
}

void ZigbeeShell::UartCallback(const struct device *dev, struct uart_event *evt, void *user_data)
{
	int err;
	static uint16_t pos;
	uint32_t ret;
	ZigbeeShell *shell = reinterpret_cast<ZigbeeShell *>(user_data);

	switch (evt->type) {
	case UART_TX_DONE:
		LOG_DBG("Tx sent %d bytes", evt->data.tx.len);
		break;

	case UART_TX_ABORTED:
		LOG_ERR("Tx aborted");
		break;

	case UART_RX_RDY:
		LOG_HEXDUMP_DBG(evt->data.rx.buf, evt->data.rx.len, "Uart RX");
		if (evt->data.rx.len > ring_buf_space_get(&shell->mShellRspRb)) {
			LOG_ERR("Not enough buffer to store data! Drop old data.");
			ret = ring_buf_get(&shell->mShellRspRb,
					   NULL,
					   evt->data.rx.len - ring_buf_space_get(&shell->mShellRspRb));
			LOG_ERR("Drop %d of ring buffer", ret);
		}
		/* Store received data to the ring buffer. */
		ret = ring_buf_put(&shell->mShellRspRb, evt->data.rx.buf + pos, evt->data.rx.len);
		if (ret != evt->data.rx.len) {
			LOG_ERR("Fail to put to ring buffer");
		}
		k_work_submit(&shell->mUartWork);
		pos += evt->data.rx.len;
		break;

	case UART_RX_BUF_REQUEST:
	{
		pos = 0;
		LOG_DBG("RX_REQUEST: %p", shell->mNextUartBuf);
		err = uart_rx_buf_rsp(shell->mUartDev,
				      shell->mNextUartBuf,
				      sizeof(shell->mUartRxBuf[0]));
		if (err) {
			LOG_WRN("UART RX buf rsp: %d", err);
		}
		break;
	}

	case UART_RX_BUF_RELEASED:
		LOG_DBG("RX_RELEASED: %p", evt->data.rx_buf.buf);
		shell->mNextUartBuf = evt->data.rx_buf.buf;
		break;

	case UART_RX_DISABLED:
		LOG_ERR("RX_DISABLED");
		break;

	case UART_RX_STOPPED:
		LOG_ERR("RX_STOPPED");
		break;
	}
}

size_t ZigbeeShell::ParseShellMessage(const char * szMsg)
{
	size_t parsed = 0, total_parsed = 0;
	char *p, *end;

	/* Parse network join message */
	p = strstr(szMsg, ZB_SHELL_MSG_JOIN_NETWORK);
	if (p != nullptr) {
		p = strstr(p, "Extended PAN ID: ");
		if (p != nullptr) {
			p = p + strlen("Extended PAN ID: ");
			memcpy(this->mEvent.Bdb.ext_pan_id, p, EXT_PAN_ID_SIZE);
			this->mEvent.Bdb.ext_pan_id[EXT_PAN_ID_SIZE] = 0;
			p = strstr(p, "PAN ID: ");
			if (p != nullptr) {
				p = p + strlen("PAN ID: ");
				this->mEvent.Bdb.pan_id = strtol(p, &end, 16);
				if (p != end) {
					LOG_INF("Joined network. Ext PAN ID: %s, PAN ID: 0x%04hx",
							this->mEvent.Bdb.ext_pan_id, this->mEvent.Bdb.pan_id);
					p = strstr(szMsg, ZB_SHELL_MSG_REJOIN);
					if (p != nullptr) {
						this->mEvent_CB(this, kEvent_NetworkRejoin);
					} else {
						this->mEvent_CB(this, kEvent_NetworkSteering);
					}
					parsed = end - szMsg;
				}
			}
		}
	}
	total_parsed = (parsed > total_parsed) ? parsed : total_parsed;
	/* Device annoucement message */
	p = strstr(szMsg, ZB_SHELL_MSG_DEVICE_REJOIN);
	if ((p != nullptr) && (p > szMsg)) {
		uint16_t dev_addr;

		parsed = p - mParserBuffer + strlen(ZB_SHELL_MSG_DEVICE_REJOIN) + strlen("xxxx)");
		dev_addr = strtol(p + strlen(ZB_SHELL_MSG_DEVICE_REJOIN), NULL, 16);
		LOG_INF("DEV announce: 0x%04hx", dev_addr);
		this->mEvent.Zdo.addr = dev_addr;
		this->mEvent_CB(this, kEvent_DeviceAnnounceRsp);
	}
	total_parsed = (parsed > total_parsed) ? parsed : total_parsed;
	LOG_DBG("%d bytes parsed", total_parsed);

	return total_parsed;
}

ZigbeeShell::ZigbeeShell(void)
{
	int err;

	k_work_init(&mUartWork, UartWorkHandler);
	k_sem_init(&mCmdSem, 0, 1);

	mUartDev = device_get_binding(CONFIG_ZIGBEE_SHELL_DEVICE_NAME);
	if (!mUartDev) {
		LOG_ERR("Failed to get the device");
	}
	err = uart_callback_set(mUartDev, UartCallback, this);
	if (err != 0) {
		LOG_ERR("Failed to set callback: %d", err);
	}
	mNextUartBuf = mUartRxBuf[1];
	err = uart_rx_enable(mUartDev, mUartRxBuf[0], UART_BUF_SIZE, 50000);
	if (err != 0) {
		LOG_ERR("Failed to enable RX: %d", err);
	}
	ring_buf_init(&mShellRspRb, sizeof(mShellRspBuffer), mShellRspBuffer);

	k_sleep(K_MSEC(10));

	err = WriteCmd("kernel reboot cold", nullptr);
	if (err) {
		LOG_ERR("Fail to reboot Zigbee shell");
	}

	k_sleep(K_MSEC(100));

	err = WriteCmd("shell colors off", ShellRspHandler);
	if (err) {
		LOG_ERR("Fail to shell color");
	}
	err = WriteCmd("shell echo off", ShellRspHandler);
	if (err) {
		LOG_ERR("Fail to set echo");
	}
}

int ZigbeeShell::BdbStart(void)
{
	int err = 0;

	err = WriteCmd("bdb role zc", GeneralRspHandler);
	if (err) {
		return err;
	}
	err = WriteCmd("bdb start", GeneralRspHandler);
	if (err) {
		return err;
	}
	err = WriteCmd("bdb legacy enable", GeneralRspHandler);
	if (err) {
		return err;
	}

	return err;
}

int ZigbeeShell::NetworkSteering(void)
{
	return WriteCmd("bdb start", GeneralRspHandler);
}

int ZigbeeShell::ZdoActiveEpReq(uint16_t addr)
{
	int err = 0;
	char cmd[MAX_ZIGBEE_CMD_LEN];

	LOG_INF("Request active endpoint of addr: 0x%04hx", addr);
	sprintf(cmd, "zdo active_ep 0x%04hx", addr);
	err = WriteCmd(cmd, ZdoActiveEpRspHandler);

	return err;
}

int ZigbeeShell::ZdoSimpleDescReq(uint16_t addr, uint8_t ep)
{
	int err = 0;
	char cmd[MAX_ZIGBEE_CMD_LEN];

	LOG_INF("Request simple descriptor of addr: 0x%04hx ep: %d ", addr, ep);
	sprintf(cmd, "zdo simple_desc_req 0x%04hx %d", addr, ep);
	err = WriteCmd(cmd, ZdoSimpleDescRspHandler);

	return err;
}

int ZigbeeShell::ZclCmd(uint16_t addr, uint8_t ep, uint16_t cluster, uint16_t cmd_id)
{
	int err = 0;
	char cmd[MAX_ZIGBEE_CMD_LEN];

	LOG_INF("Send ZCL cmd. addr: 0x%04hx ep: %d cluster: 0x%04hx cmd_id: 0x%04hx", addr, ep, cluster, cmd_id);
	sprintf(cmd, "zcl cmd -d 0x%04hx %d 0x%04hx 0x%04hx", addr, ep, cluster, cmd_id);
	err = WriteCmd(cmd, GeneralRspHandler);

	return err;
}

int ZigbeeShell::ZclAttrRead(uint16_t addr,
			     uint8_t ep,
			     uint16_t profile_id,
			     enum Cluster_t cluster_id,
			     uint16_t attr_id)
{
	int err = 0;
	char cmd[MAX_ZIGBEE_CMD_LEN];

	LOG_INF("Read ZCL attr addr: 0x%04hx ep: %d cluster: 0x%04hx attr_id: 0x%04hx", addr, ep, cluster_id, attr_id);
	sprintf(cmd, "zcl attr read 0x%04hx %d 0x%04hx 0x%04hx 0x%04hx", addr, ep, cluster_id, profile_id, attr_id);
	mEvent.Zcl.addr = addr;
	mEvent.Zcl.ep = ep;
	mEvent.Zcl.cluster_id = cluster_id;
	mEvent.Zcl.attr_id = attr_id;
	err = WriteCmd(cmd, ZclAttrReadRspHandler);

	return err;
}

int ZigbeeShell::ZdoMatchDesc(uint16_t dst_addr,
			      uint16_t req_addr,
			      uint16_t profile_id,
			      uint8_t in_cluster_cnt,
			      uint16_t *in_clusters,
			      uint8_t out_cluster_cnt,
			      uint16_t *out_clusters)
{
	int err = 0;
	char cmd[MAX_ZIGBEE_CMD_LEN], in_cluster_str[32], out_cluster_str[32];

	memset(cmd, 0, sizeof(cmd));
	memset(in_cluster_str, 0, sizeof(in_cluster_str));
	memset(out_cluster_str, 0, sizeof(out_cluster_str));
	for (auto i = 0; i < in_cluster_cnt; i++) {
		sprintf(in_cluster_str + 2*i, "%hx ", *(in_clusters + 2*i));
	}
	for (auto i = 0; i < out_cluster_cnt; i++) {
		sprintf(out_cluster_str + 2*i, "%hx ", *(out_clusters + 2*i));
	}
	sprintf(cmd, "zdo match_desc 0x%04hx 0x%04hx 0x%04hx %d %s %d %s -t 5",
		dst_addr, req_addr, profile_id, in_cluster_cnt, in_cluster_str, out_cluster_cnt, out_cluster_str);
	err = WriteCmd(cmd, ZdoActiveEpRspHandler);

	return err;
}

void ZigbeeShell::SetEventCallback(zigbee_event_handler_t zigbee_event_handler)
{
	mEvent_CB = zigbee_event_handler;
}
```

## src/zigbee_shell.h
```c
/*
 * Copyright (c) 2022 Nordic Semiconductor ASA
 *
 * SPDX-License-Identifier: LicenseRef-Nordic-5-Clause
 */

#pragma once

#include <functional>
#include <zephyr/kernel.h>
#include <zephyr/sys/ring_buffer.h>

#define ZB_SHELL_MSG_PROMPT "uart:~$"
#define ZB_SHELL_MSG_CMD_DONE "Done"
#define ZB_SHELL_MSG_CMD_ERROR "Error"
#define ZB_SHELL_MSG_DEVICE_REJOIN "rejoined (short: 0x"
#define ZB_SHELL_MSG_JOIN_NETWORK "Joined network successfully"
#define ZB_SHELL_MSG_REJOIN "on reboot signal"

#define UNPARSED_BUF_LEN 1024
#define MAX_ZIGBEE_CMD_LEN 128
#define UART_BUF_SIZE	256
#define UART_RX_BUF_NUM	2
#define ZB_ZCL_MAX_ATTR_SIZE 40
#define EXT_PAN_ID_SIZE 16

class ZigbeeShell
{
public:
	enum Event_t
	{
		kEvent_NetworkRejoin,
		kEvent_NetworkSteering,
		kEvent_DeviceAnnounceRsp,
		kEvent_ActiveEpRsp,
		kEvent_SimpleDescRsp,
		kEvent_ZclAttrRead
	};
	enum Cluster_t : uint16_t
	{
		kCluster_OnOff = 0x0006,
		kCluster_LevelControl = 0x0008
	};
	/* On/Off cluster attribute identifiers */
	enum OnOffAttr_t : uint16_t
	{
		kOnOffAttr_OnOff = 0x0000
	};
	enum ZclAttrType_t : uint8_t
	{
		kZclAttrType_BOOL = 0x10
	};

	struct BdbEvent {
		char ext_pan_id[EXT_PAN_ID_SIZE + 1];
		uint16_t pan_id;
	};
	struct ZdoEvent {
		uint16_t addr;
		uint8_t ep;
		uint16_t dev_id;
	};
	struct ZclEvent {
		uint16_t addr;
		uint8_t ep;
		uint16_t cluster_id;
		uint16_t attr_id;
		uint8_t type;
		char value[ZB_ZCL_MAX_ATTR_SIZE + 1];
		size_t len;
	};
	union {
		struct BdbEvent Bdb;
		struct ZdoEvent Zdo;
		struct ZclEvent Zcl;
	} mEvent;

	typedef void (*zigbee_event_handler_t)(ZigbeeShell *, Event_t);

	ZigbeeShell();
	int BdbStart();
	int NetworkSteering();
	int ZdoActiveEpReq(uint16_t addr);
	int ZdoSimpleDescReq(uint16_t addr, uint8_t ep);
	int ZclCmd(uint16_t addr, uint8_t ep, uint16_t cluster, uint16_t cmd_id);
	int ZclAttrRead(uint16_t addr,
			uint8_t ep,
			uint16_t profile_id,
			enum Cluster_t cluster_id,
			uint16_t attr_id);
	int ZdoMatchDesc(uint16_t dst_addr,
			 uint16_t req_addr,
			 uint16_t profile_id,
			 uint8_t in_cluster_cnt,
			 uint16_t *in_clusters,
			 uint8_t out_cluster_cnt,
			 uint16_t *out_clusters);
	void SetEventCallback(zigbee_event_handler_t zigbee_event_handler);

private:
	typedef size_t (*ZigbeeResponseHandler)(ZigbeeShell *shell, const char *data, size_t len);

	struct k_sem mCmdSem;
	struct ZigbeeCmd {
		char command[MAX_ZIGBEE_CMD_LEN + 1];
		ZigbeeResponseHandler handler;
		int result;
	};
	struct ZigbeeCmd mZigbeeCmd;
	const struct device *mUartDev;
	uint8_t *mNextUartBuf;
	uint8_t mUartRxBuf[UART_RX_BUF_NUM][UART_BUF_SIZE];
	struct ring_buf mShellRspRb;
	static void UartCallback(const struct device *dev, struct uart_event *evt, void *user_data);
	uint8_t mShellRspBuffer[UNPARSED_BUF_LEN];
	char mParserBuffer[UNPARSED_BUF_LEN];
	static void UartWorkHandler(struct k_work *work);
	struct k_work mUartWork;

	size_t ParseShellMessage(const char * szMsg);
	int WriteCmd(const char *cmd, ZigbeeResponseHandler cmd_handler);
	zigbee_event_handler_t mEvent_CB;

	static size_t ShellRspHandler(ZigbeeShell *shell, const char *data, size_t len);
	static size_t GeneralRspHandler(ZigbeeShell *shell, const char *data, size_t len);
	static size_t ZdoActiveEpRspHandler(ZigbeeShell *shell, const char *data, size_t len);
	static size_t ZdoSimpleDescRspHandler(ZigbeeShell *shell, const char *data, size_t len);
	static size_t ZclAttrReadRspHandler(ZigbeeShell *shell,const char *data, size_t len);
};
```
